# N32L406 register map
Vendor: Nationstech Ltd.; File version: 1.0
Registers are 32-bit, read-write, reset 0x0 unless marked. A register's access mark holds for its fields unless they carry their own. Offsets are from the block's base; [hi:lo] are bit positions.

## ID — ID registers
Base 0xE000ED00
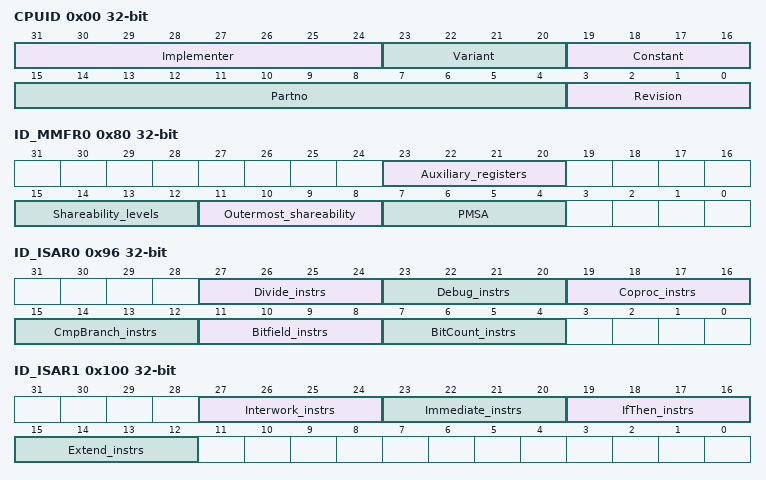
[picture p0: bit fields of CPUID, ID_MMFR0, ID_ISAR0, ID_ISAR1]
0x00 CPUID ro — Identification information for the processor
  [31:24] Implementer — Implementer code
  [23:20] Variant — Implementation defined
  [19:16] Constant — Indicates the architecture
  [15:4] Partno — Indicates part number
  [3:0] Revision — Indicates revision
0x64 ID_PFR0 ro
  [7:4] State1 — Thumb instruction set support
    3=Thumb_Thumb2
0x68 ID_PFR1 ro
  [11:8] M_Profile — M profile programmers' model
    2=Two_stack
0x72 ID_DFR0 ro
  [23:20] M_Profile — Debug model, M profile
    0=Not_supported; 1=Supported
0x76 ID_AFR0 ro — Implementation defined features
0x80 ID_MMFR0 ro — Memory Model Features
  [23:20] Auxiliary_registers — Indicates support for Auxiliary registers
    0=Not_supported; 1=Supported
  [15:12] Shareability_levels — Indicates the number of shareability levels implemented
    0=One_level
  [11:8] Outermost_shareability — Indicates the outermost shareability domain implemented
    0=Non_cacheable; 15=Ignored
  [7:4] PMSA — Indicates support for a PMSA
    0=Not_supported; 3=PMSAv7
0x84 ID_MMFR1 ro — Memory Model Features
0x88 ID_MMFR2 ro — Memory Model Features
  [27:24] WFI — Indicates support for wait-for-interrupt stalling.
    0=Not_supported; 1=Supported
0x92 ID_MMFR3 ro — Memory Model Features
0x96 ID_ISAR0 ro — Instruction Set Attributes
  [27:24] Divide_instrs — Indicates the supported divide instructions
    0=Not_supported; 1=Supported
  [23:20] Debug_instrs — Indicates the supported debug instructions
    0=Not_supported; 1=Supported
  [19:16] Coproc_instrs — Indicates the supported coprocessor instructions
    0=None; 1=Generic; 2=Generic2; 3=MCRR_MRRC; 4=MCRR2_MRRC2
  [15:12] CmpBranch_instrs — Indicates support for combined compare and branch instructions.
    0=Not_supported; 1=Supported
  [11:8] Bitfield_instrs — Indicates support for bitfield instructions.
    0=Not_supported; 1=Supported
  [7:4] BitCount_instrs — Indicates support for bit counting instructions.
    0=Not_supported; 1=Supported
0x100 ID_ISAR1 ro — Instruction Set Attributes
  [27:24] Interwork_instrs — Indicates support for instructions that branch between ARM and Thumb code.
    0=None; 1=BX; 2=BX_BLX2
  [23:20] Immediate_instrs — Indicates support for immediate instructions.
    0=Not_supported; 1=Supported
  [19:16] IfThen_instrs — Indicates support for IfThen instructions.
    0=Not_supported; 1=Supported
  [15:12] Extend_instrs — Indicates support for sign or zero extend instructions.
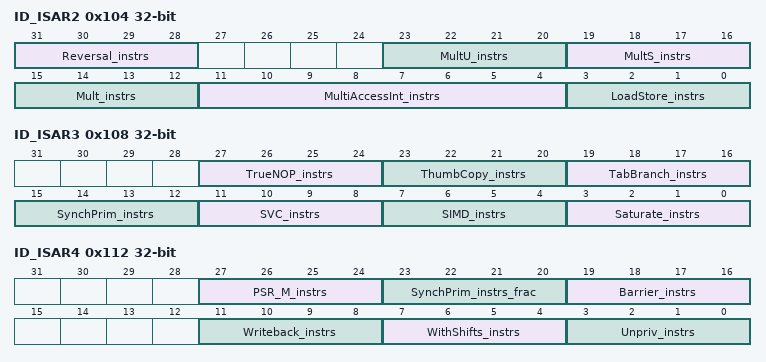
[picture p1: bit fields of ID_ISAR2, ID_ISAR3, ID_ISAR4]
0x104 ID_ISAR2 ro — Instruction Set Attributes
  [31:28] Reversal_instrs — Indicates the supported reversal instructions.
  [23:20] MultU_instrs — Indicates the supported advanced unsigned multiply instructions.
  [19:16] MultS_instrs — Indicates the supported advanced signed multiply instructions.
  [15:12] Mult_instrs — Indicates the supported additional multiply instructions.
  [11:4] MultiAccessInt_instrs — Indicates the supported multi-access interruptible instructions.
  [3:0] LoadStore_instrs — Indicates the supported additional load and store instructions.
0x108 ID_ISAR3 ro — Instruction Set Attributes
  [27:24] TrueNOP_instrs — Indicates support for true NOP instructions.
    0=Not_supported; 1=Supported
  [23:20] ThumbCopy_instrs — Indicates support for Thumb copy instructions.
    0=Not_supported; 1=Supported
  [19:16] TabBranch_instrs — Indicates support for table branch instructions.
    0=Not_supported; 1=Supported
  [15:12] SynchPrim_instrs — Indicates support for synchronization primitive instructions.
  [11:8] SVC_instrs — Indicates support for SVC instructions.
    0=Not_supported; 1=Supported
  [7:4] SIMD_instrs — Indicates support for Single Instruction Multiple Data (SIMD) instructions.
  [3:0] Saturate_instrs — Indicates support for saturate instructions.
    0=Not_supported; 1=Supported
0x112 ID_ISAR4 ro — Instruction Set Attributes
  [27:24] PSR_M_instrs — Indicates support for saturate instructions.
    0=Not_supported; 1=Supported
  [23:20] SynchPrim_instrs_frac — Indicates support for Synchronization Primitives
  [19:16] Barrier_instrs — Indicates the supported barrier instructions.
    0=Not_supported; 1=Supported
  [11:8] Writeback_instrs — Indicates support for Writeback addressing modes
    0=Basic; 1=Full
  [7:4] WithShifts_instrs — Indicates the support for instructions with shifts:
  [3:0] Unpriv_instrs — Indicates the supported unprivileged instructions
